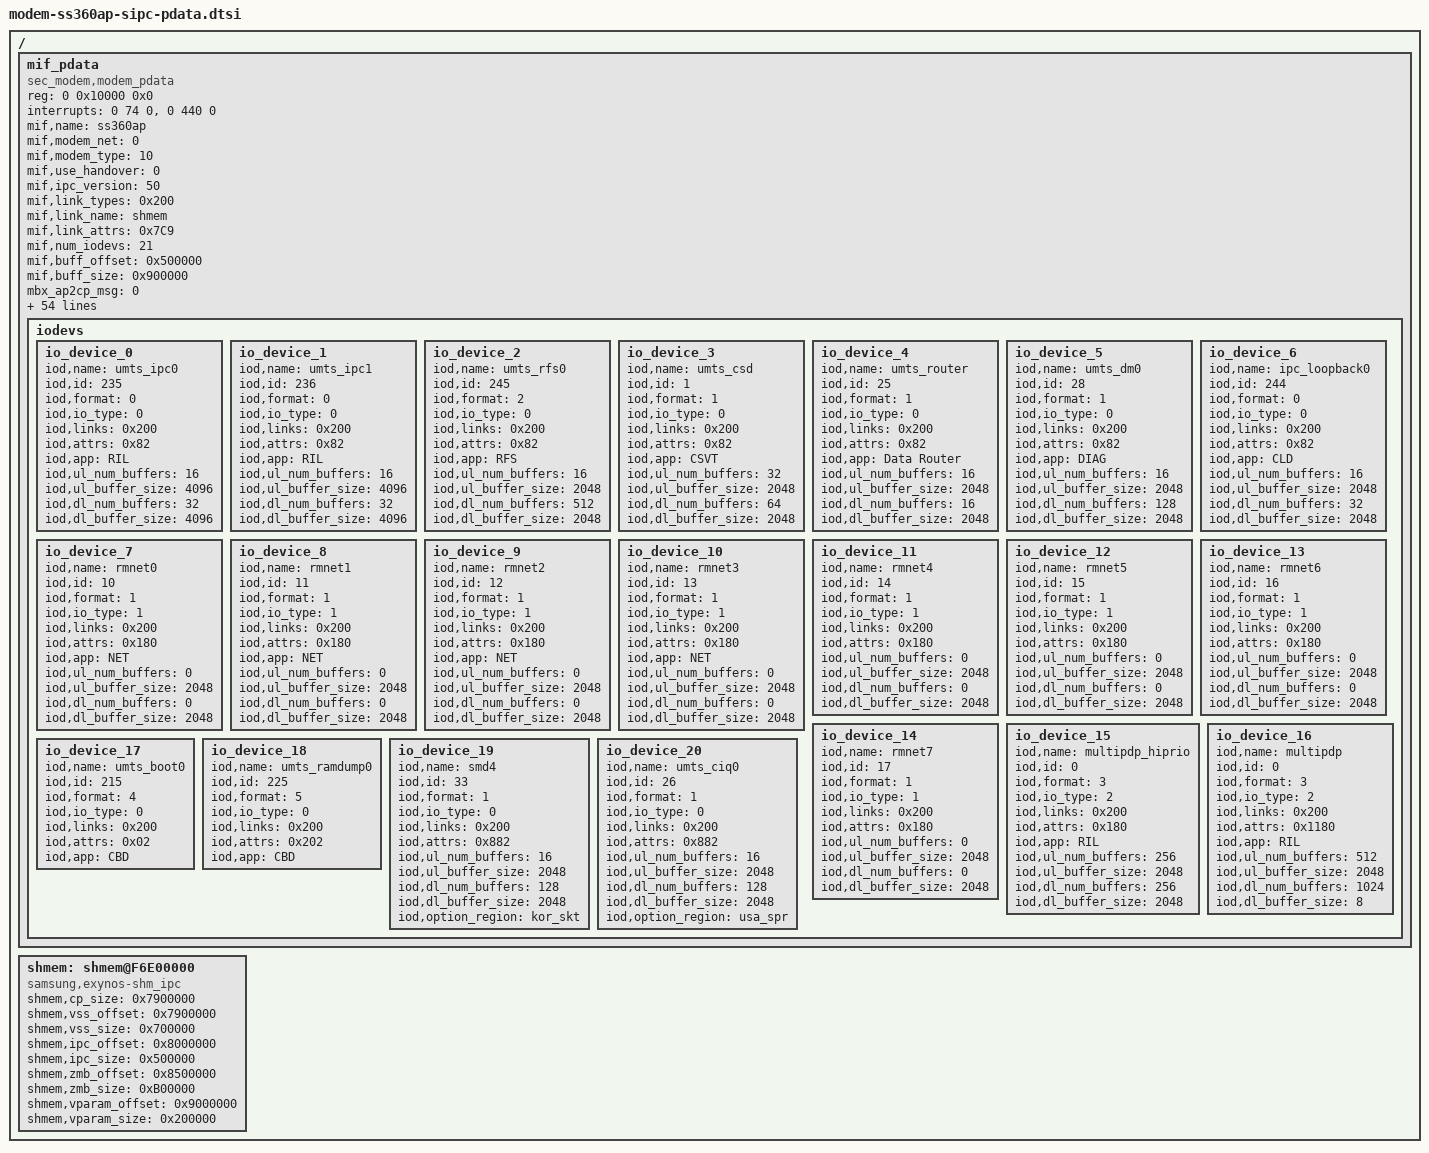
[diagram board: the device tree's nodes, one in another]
/*
 * SAMSUNG UNIVERSAL8895 board device tree source
 *
 * Copyright (c) 2016 Samsung Electronics Co., Ltd.
 *             http://www.samsung.com
 *
 * This program is free software; you can redistribute it and/or modify
 * it under the terms of the GNU General Public License version 2 as
 * published by the Free Software Foundation.
*/

/ {
	fragment@mif {
		target-path = "/";
		__overlay__ {
			#address-cells = <2>;
			#size-cells = <1>;
			/* modem_interface_driver: Samsung Electronics */
			mif_pdata: mif_pdata {
				/* modem main binary start offset */
				reg = <0 0x10000 0x0>;

				compatible = "sec_modem,modem_pdata";
				status = "okay";
				interrupts = <0 74 0>, <0 440 0>; /* INTREQ_ALIVE_CP_ACTIVE, INTREQ_CP2AP_RESET_REQ */

				/* common pdata */
				mif,name = "ss360ap";
				mif,modem_net = <0>;		/* UMTS_NETWORK */
				mif,modem_type = <10>;		/* SEC_SS310AP */
				mif,use_handover = <0>;		/* not used */
				mif,ipc_version = <50>;		/* SIPC 5.0 */
				mif,link_types = <0x200>;	/* LINKDEV_SHMEM */
				mif,link_name = "shmem";
				mif,link_attrs = <0x7C9>;	/* XMIT_BTDLR(0x400) | DUMP_ALIGNED (0x200) | BOOT_ALIGNED (0x100) | MEM_DUMP (0x80) | MEM_BOOT (0x40) | DPRAM_MAGIC (0x08) | SBD_IPC (0x01) */
				mif,num_iodevs = <21>;

				/* MIF buffer information */
				mif,buff_offset = <0x500000>;
				mif,buff_size = <0x900000>;

				/* mbox pdata */
				mbx_ap2cp_msg = <0>;
				mbx_cp2ap_msg = <1>;
				mbx_ap2cp_united_status = <2>;
				mbx_cp2ap_united_status = <3>;
				mbx_ap2cp_mif_value = <4>;
				mbx_ap2cp_kerneltime = <9>;

				mif,int_ap2cp_msg = <0>;
				mif,int_ap2cp_wakeup = <1>;
				mif,int_ap2cp_status = <2>;
				mif,int_ap2cp_active = <3>;

				mif,irq_cp2ap_msg = <0>;
				mif,irq_cp2ap_status = <2>;
				mif,irq_cp2ap_active = <3>;
				mif,irq_cp2ap_wakelock = <8>;
				mif,irq_cp2ap_ratmode = <9>;

				/* mbox pdata for performance request */
				mbx_cp2ap_dvfsreq_cpu = <5>;
				mbx_cp2ap_dvfsreq_mif = <6>;
				mbx_cp2ap_dvfsreq_int = <7>;

				mif,irq_cp2ap_perf_req_cpu = <5>; /* CP2AP_DVFSREQ_CPU */
				mif,irq_cp2ap_perf_req_mif = <6>; /* CP2AP_DVFSREQ_MIF */
				mif,irq_cp2ap_perf_req_int = <7>; /* CP2AP_DVFSREQ_INT */


				/* mbox pdata for sbi(status bit info) */
				sbi_cp_rat_mode_mask = <0x3f>;
				sbi_cp_rat_mode_pos = <26>;
				sbi_cp_evs_mode_mask = <0x1>;
				sbi_cp_evs_mode_pos = <7>;
				sbi_cp_wakelock_mask = <0x1>;
				sbi_cp_wakelock_pos = <6>;
				sbi_lte_active_mask = <0x1>;
				sbi_lte_active_pos = <5>;
				sbi_cp_status_mask = <0xf>;
				sbi_cp_status_pos = <1>;
				sbi_cp2ap_wakelock_mask = <0x1>;
				sbi_cp2ap_wakelock_pos = <6>;
				sbi_pda_active_mask = <0x1>;
				sbi_pda_active_pos = <5>;
				sbi_ap_status_mask = <0xf>;
				sbi_ap_status_pos = <1>;

				sbi_crash_type_mask = <0xf>;
				sbi_crash_type_pos = <23>;
				sbi_device_type_mask = <0x1f>;
				sbi_device_type_pos = <18>;
				sbi_ext_backtrace_mask = <0x1>;
				sbi_ext_backtrace_pos = <17>;
				sbi_ds_det_mask = <0x3>;
				sbi_ds_det_pos = <14>;
				sbi_sys_rev_mask = <0xff>;
				sbi_sys_rev_pos = <6>;

				sbi_lockval_cp2ap_dvfsreq_endian_mask = <0x1>;
				sbi_lockval_cp2ap_dvfsreq_endian_pos = <31>;
				sbi_lockval_cp2ap_dvfsreq_index_mask = <0x7fff>;
				sbi_lockval_cp2ap_dvfsreq_index_pos = <0>;

				sbi_ap2cp_kerneltime_sec_mask = <0xfff>;
				sbi_ap2cp_kerneltime_sec_pos = <20>;
				sbi_ap2cp_kerneltime_usec_mask = <0xfffff>;
				sbi_ap2cp_kerneltime_usec_pos = <0>;


				iodevs {
					io_device_0 {
						iod,name = "umts_ipc0";
						iod,id = <235>;
						iod,format = <0>;		/* IPC_FMT */
						iod,io_type = <0>;		/* IODEV_MISC */
						iod,links = <0x200>;		/* LINKDEV_SHMEM */
						iod,attrs = <0x82>;		/* ATTR_SBD_IPC | ATTR_SIPC5 */
						iod,app = "RIL";
						iod,ul_num_buffers = <16>;
						iod,ul_buffer_size = <4096>;
						iod,dl_num_buffers = <32>;
						iod,dl_buffer_size = <4096>;
					};
					io_device_1 {
						iod,name = "umts_ipc1";
						iod,id = <236>;
						iod,format = <0>;		/* IPC_FMT */
						iod,io_type = <0>;		/* IODEV_MISC */
						iod,links = <0x200>;		/* LINKDEV_SHMEM */
						iod,attrs = <0x82>;		/* ATTR_SBD_IPC | ATTR_SIPC5 */
						iod,app = "RIL";
						iod,ul_num_buffers = <16>;
						iod,ul_buffer_size = <4096>;
						iod,dl_num_buffers = <32>;
						iod,dl_buffer_size = <4096>;
					};
					io_device_2 {
						iod,name = "umts_rfs0";
						iod,id = <245>;
						iod,format = <2>;		/* IPC_RFS */
						iod,io_type = <0>;
						iod,links = <0x200>;
						iod,attrs = <0x82>;
						iod,app = "RFS";
						iod,ul_num_buffers = <16>;
						iod,ul_buffer_size = <2048>;
						iod,dl_num_buffers = <512>;
						iod,dl_buffer_size = <2048>;
					};
					io_device_3 {
						iod,name = "umts_csd";
						iod,id = <1>;
						iod,format = <1>;
						iod,io_type = <0>;
						iod,links = <0x200>;
						iod,attrs = <0x82>;
						iod,app = "CSVT";
						iod,ul_num_buffers = <32>;
						iod,ul_buffer_size = <2048>;
						iod,dl_num_buffers = <64>;
						iod,dl_buffer_size = <2048>;
					};
					io_device_4 {
						iod,name = "umts_router";
						iod,id = <25>;
						iod,format = <1>;
						iod,io_type = <0>;
						iod,links = <0x200>;
						iod,attrs = <0x82>;
						iod,app = "Data Router";
						iod,ul_num_buffers = <16>;
						iod,ul_buffer_size = <2048>;
						iod,dl_num_buffers = <16>;
						iod,dl_buffer_size = <2048>;
					};
					io_device_5 {
						iod,name = "umts_dm0";
						iod,id = <28>;
						iod,format = <1>;
						iod,io_type = <0>;
						iod,links = <0x200>;
						iod,attrs = <0x82>;
						iod,app = "DIAG";
						iod,ul_num_buffers = <16>;
						iod,ul_buffer_size = <2048>;
						iod,dl_num_buffers = <128>;
						iod,dl_buffer_size = <2048>;
					};
					io_device_6 {
						iod,name = "ipc_loopback0";
						iod,id = <244>;
						iod,format = <0>;
						iod,io_type = <0>;
						iod,links = <0x200>;
						iod,attrs = <0x82>;
						iod,app = "CLD";
						iod,ul_num_buffers = <16>;
						iod,ul_buffer_size = <2048>;
						iod,dl_num_buffers = <32>;
						iod,dl_buffer_size = <2048>;
					};
					io_device_7 {
						iod,name = "rmnet0";
						iod,id = <10>;
						iod,format = <1>;
						iod,io_type = <1>;		/* IODEV_NET */
						iod,links = <0x200>;
						iod,attrs = <0x180>;		/* ATTR_SBD_IPC (0x80) | ATTR_NO_LINK_HDR(0x100) */
						iod,app = "NET";
						iod,ul_num_buffers = <0>;
						iod,ul_buffer_size = <2048>;
						iod,dl_num_buffers = <0>;
						iod,dl_buffer_size = <2048>;
					};
					io_device_8 {
						iod,name = "rmnet1";
						iod,id = <11>;
						iod,format = <1>;
						iod,io_type = <1>;
						iod,links = <0x200>;
						iod,attrs = <0x180>;
						iod,app = "NET";
						iod,ul_num_buffers = <0>;
						iod,ul_buffer_size = <2048>;
						iod,dl_num_buffers = <0>;
						iod,dl_buffer_size = <2048>;
					};
					io_device_9 {
						iod,name = "rmnet2";
						iod,id = <12>;
						iod,format = <1>;
						iod,io_type = <1>;
						iod,links = <0x200>;
						iod,attrs = <0x180>;
						iod,app = "NET";
						iod,ul_num_buffers = <0>;
						iod,ul_buffer_size = <2048>;
						iod,dl_num_buffers = <0>;
						iod,dl_buffer_size = <2048>;
					};
					io_device_10 {
						iod,name = "rmnet3";
						iod,id = <13>;
						iod,format = <1>;
						iod,io_type = <1>;
						iod,links = <0x200>;
						iod,attrs = <0x180>;
						iod,app = "NET";
						iod,ul_num_buffers = <0>;
						iod,ul_buffer_size = <2048>;
						iod,dl_num_buffers = <0>;
						iod,dl_buffer_size = <2048>;
					};
					io_device_11 {
						iod,name = "rmnet4";
						iod,id = <14>;
						iod,format = <1>;
						iod,io_type = <1>;
						iod,links = <0x200>;
						iod,attrs = <0x180>;	/* ATTR_NO_LINK_HDR(0x100) | ATTR_SBD_IPC (0x80) */
						iod,ul_num_buffers = <0>;
						iod,ul_buffer_size = <2048>;
						iod,dl_num_buffers = <0>;
						iod,dl_buffer_size = <2048>;
					};
					io_device_12 {
						iod,name = "rmnet5";
						iod,id = <15>;
						iod,format = <1>;
						iod,io_type = <1>;
						iod,links = <0x200>;
						iod,attrs = <0x180>;
						iod,ul_num_buffers = <0>;
						iod,ul_buffer_size = <2048>;
						iod,dl_num_buffers = <0>;
						iod,dl_buffer_size = <2048>;
					};
					io_device_13 {
						iod,name = "rmnet6";
						iod,id = <16>;
						iod,format = <1>;
						iod,io_type = <1>;
						iod,links = <0x200>;
						iod,attrs = <0x180>;
						iod,ul_num_buffers = <0>;
						iod,ul_buffer_size = <2048>;
						iod,dl_num_buffers = <0>;
						iod,dl_buffer_size = <2048>;
					};
					io_device_14 {
						iod,name = "rmnet7";
						iod,id = <17>;
						iod,format = <1>;
						iod,io_type = <1>;
						iod,links = <0x200>;
						iod,attrs = <0x180>;
						iod,ul_num_buffers = <0>;
						iod,ul_buffer_size = <2048>;
						iod,dl_num_buffers = <0>;
						iod,dl_buffer_size = <2048>;
					};
					io_device_15 {
						iod,name = "multipdp_hiprio";
						iod,id = <0>;
						iod,format = <3>;		/* IPC_MULTI_RAW */
						iod,io_type = <2>;		/* IODEV_DUMMY */
						iod,links = <0x200>;
						iod,attrs = <0x180>;
						iod,app = "RIL";
						iod,ul_num_buffers = <256>;
						iod,ul_buffer_size = <2048>;
						iod,dl_num_buffers = <256>;
						iod,dl_buffer_size = <2048>;
					};
					io_device_16 {
						iod,name = "multipdp";
						iod,id = <0>;
						iod,format = <3>;		/* IPC_MULTI_RAW */
						iod,io_type = <2>;		/* IODEV_DUMMY */
						iod,links = <0x200>;
						iod,attrs = <0x1180>;		/* ATTR_ZEROCOPY (0x1000) | ATTR_SBD_IPC (0x80) | ATTR_NO_LINK_HDR (0x100) */
						iod,app = "RIL";
						iod,ul_num_buffers = <512>;
						iod,ul_buffer_size = <2048>;
						iod,dl_num_buffers = <1024>;
						iod,dl_buffer_size = <8>;
					};
					io_device_17 {
						iod,name = "umts_boot0";
						iod,id = <215>;
						iod,format = <4>;		/* IPC_BOOT */
						iod,io_type = <0>;
						iod,links = <0x200>;
						iod,attrs = <0x02>;
						iod,app = "CBD";
					};
					io_device_18 {
						iod,name = "umts_ramdump0";
						iod,id = <225>;
						iod,format = <5>;		/* IPC_DUMP */
						iod,io_type = <0>;
						iod,links = <0x200>;
						iod,attrs = <0x202>;		/* ATTR_NO_CHECK_MAXQ | ATTR_SIPC5 */
						iod,app = "CBD";
					};
					io_device_19 {
						iod,name = "smd4";
						iod,id = <33>;
						iod,format = <1>;
						iod,io_type = <0>;
						iod,links = <0x200>;
						iod,attrs = <0x882>;
						iod,ul_num_buffers = <16>;
						iod,ul_buffer_size = <2048>;
						iod,dl_num_buffers = <128>;
						iod,dl_buffer_size = <2048>;
						iod,option_region = "kor_skt";
					};
					io_device_20 {
						iod,name = "umts_ciq0";
						iod,id = <26>;
						iod,format = <1>;
						iod,io_type = <0>;
						iod,links = <0x200>;
						iod,attrs = <0x882>;
						iod,ul_num_buffers = <16>;
						iod,ul_buffer_size = <2048>;
						iod,dl_num_buffers = <128>;
						iod,dl_buffer_size = <2048>;
						iod,option_region = "usa_spr";
					};
				}; /* end of iodevs */
			}; /* end of mif_pdata */

			shmem: shmem@F6E00000 {
				compatible = "samsung,exynos-shm_ipc";

				shmem,cp_size = <0x7900000>; /* CP 121MB */
				shmem,vss_offset = <0x7900000>;
				shmem,vss_size = <0x700000>; /* VSS 7MB */
				shmem,ipc_offset = <0x8000000>; /* 128MB(CP 121MB + VSS 7MB) */
				shmem,ipc_size = <0x500000>; /* 5MB */
				shmem,zmb_offset = <0x8500000>; /* 133MB(CP 121MB + VSS 7MB + IPC 5MB) */
				shmem,zmb_size = <0xB00000>; /* 11MB */
				shmem,vparam_offset = <0x9000000>;
				shmem,vparam_size = <0x200000>;
			};
		};
	};
};
